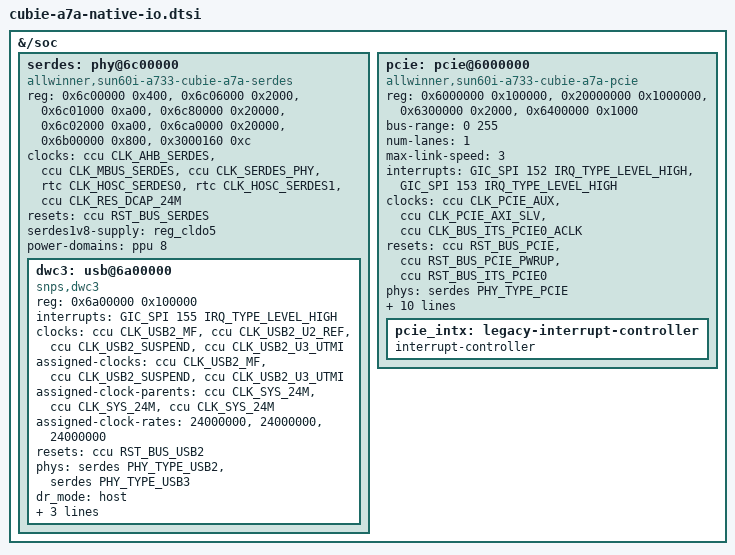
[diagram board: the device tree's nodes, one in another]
// SPDX-License-Identifier: (GPL-2.0-only OR MIT)
/* Fixed Cubie routing: combo0 -> blue USB-A, combo1 -> HAT PCIe x1.
 * Needs the cubie-a7a-board-support kmods (sun60i-a733-serdes,
 * sun60i-a733-pcie and the sun55i-pck600 override) on Fedora's own kernel;
 * they are staged behind modprobe.d until enabled peripheral by peripheral.
 * No generic PCIe fallback: it cannot own these resets, rails or SII IRQs.
 */
#include <dt-bindings/phy/phy.h>
#include <dt-bindings/clock/sun6i-rtc.h>

&{/soc} {
	serdes: phy@6c00000 {
		compatible = "allwinner,sun60i-a733-cubie-a7a-serdes";
		reg = <0x6c00000 0x400>, <0x6c06000 0x2000>,
		      <0x6c01000 0xa00>, <0x6c80000 0x20000>,
		      <0x6c02000 0xa00>, <0x6ca0000 0x20000>,
		      <0x6b00000 0x800>, <0x3000160 0xc>;
		reg-names = "subsys", "map", "combo0-top", "combo0-phy",
		            "combo1-top", "combo1-phy", "usb2-phy", "rescal";
		clocks = <&ccu CLK_AHB_SERDES>, <&ccu CLK_MBUS_SERDES>,
		         <&ccu CLK_SERDES_PHY>, <&rtc CLK_HOSC_SERDES0>,
		         <&rtc CLK_HOSC_SERDES1>, <&ccu CLK_RES_DCAP_24M>;
		clock-names = "bus", "mbus", "cfg", "ref0", "ref1", "rescal";
		resets = <&ccu RST_BUS_SERDES>;
		reset-names = "serdes";
		serdes1v8-supply = <&reg_cldo5>;
		/* USB2 domain is retained by the matching board PPU override. */
		power-domains = <&ppu 8>;
		#phy-cells = <1>;
		#address-cells = <1>;
		#size-cells = <1>;
		ranges;

		/* Child creation happens only after common bus/UTMI readiness. */
		dwc3: usb@6a00000 {
			compatible = "snps,dwc3";
			reg = <0x6a00000 0x100000>;
			interrupts = <GIC_SPI 155 IRQ_TYPE_LEVEL_HIGH>;
			clocks = <&ccu CLK_USB2_MF>, <&ccu CLK_USB2_U2_REF>,
			         <&ccu CLK_USB2_SUSPEND>, <&ccu CLK_USB2_U3_UTMI>;
			clock-names = "bus_early", "ref", "suspend", "utmi";
			assigned-clocks = <&ccu CLK_USB2_MF>, <&ccu CLK_USB2_SUSPEND>,
			                  <&ccu CLK_USB2_U3_UTMI>;
			assigned-clock-parents = <&ccu CLK_SYS_24M>, <&ccu CLK_SYS_24M>,
			                         <&ccu CLK_SYS_24M>;
			assigned-clock-rates = <24000000>, <24000000>, <24000000>;
			resets = <&ccu RST_BUS_USB2>;
			phys = <&serdes PHY_TYPE_USB2>, <&serdes PHY_TYPE_USB3>;
			phy-names = "usb2-phy", "usb3-phy";
			dr_mode = "host";
			maximum-speed = "super-speed-plus";
			snps,dis_u2_susphy_quirk;
			snps,dis_enblslpm_quirk;
		};
	};

	pcie: pcie@6000000 {
		compatible = "allwinner,sun60i-a733-cubie-a7a-pcie";
		reg = <0x6000000 0x100000>, <0x20000000 0x1000000>,
		      <0x6300000 0x2000>, <0x6400000 0x1000>;
		reg-names = "dbi", "config", "atu", "app";
		device_type = "pci";
		#address-cells = <3>;
		#size-cells = <2>;
		bus-range = <0 255>;
		ranges = <0x81000000 0 0 0x21000000 0 0x10000>,
		         <0x82000000 0 0x22000000 0x22000000 0 0x6000000>;
		num-lanes = <1>;
		max-link-speed = <3>;
		interrupts = <GIC_SPI 152 IRQ_TYPE_LEVEL_HIGH>,
		             <GIC_SPI 153 IRQ_TYPE_LEVEL_HIGH>;
		interrupt-names = "app", "msi";
		clocks = <&ccu CLK_PCIE_AUX>, <&ccu CLK_PCIE_AXI_SLV>,
		         <&ccu CLK_BUS_ITS_PCIE0_ACLK>;
		clock-names = "aux", "slv", "mstr";
		resets = <&ccu RST_BUS_PCIE>, <&ccu RST_BUS_PCIE_PWRUP>,
		         <&ccu RST_BUS_ITS_PCIE0>;
		reset-names = "app", "pwr", "core";
		phys = <&serdes PHY_TYPE_PCIE>;
		phy-names = "pcie-phy";
		power-domains = <&ppu 7>;
		pcie1v8-supply = <&reg_bldo1>;
		pcie3v3-supply = <&reg_dcdc1>;
		power-gpios = <&gpio 4 11 GPIO_ACTIVE_HIGH>;
		reset-gpios = <&gpio 4 13 GPIO_ACTIVE_LOW>;
		wake-gpios = <&gpio 4 12 GPIO_ACTIVE_LOW>;
		#interrupt-cells = <1>;
		interrupt-map-mask = <0 0 0 7>;
		interrupt-map = <0 0 0 1 &pcie_intx 0>, <0 0 0 2 &pcie_intx 1>,
		                <0 0 0 3 &pcie_intx 2>, <0 0 0 4 &pcie_intx 3>;
		/* Assertion-event demux exists; held/shared INTx remains a gate. */
		pcie_intx: legacy-interrupt-controller {
			interrupt-controller;
			#interrupt-cells = <1>;
			#address-cells = <0>;
		};
	};
};
